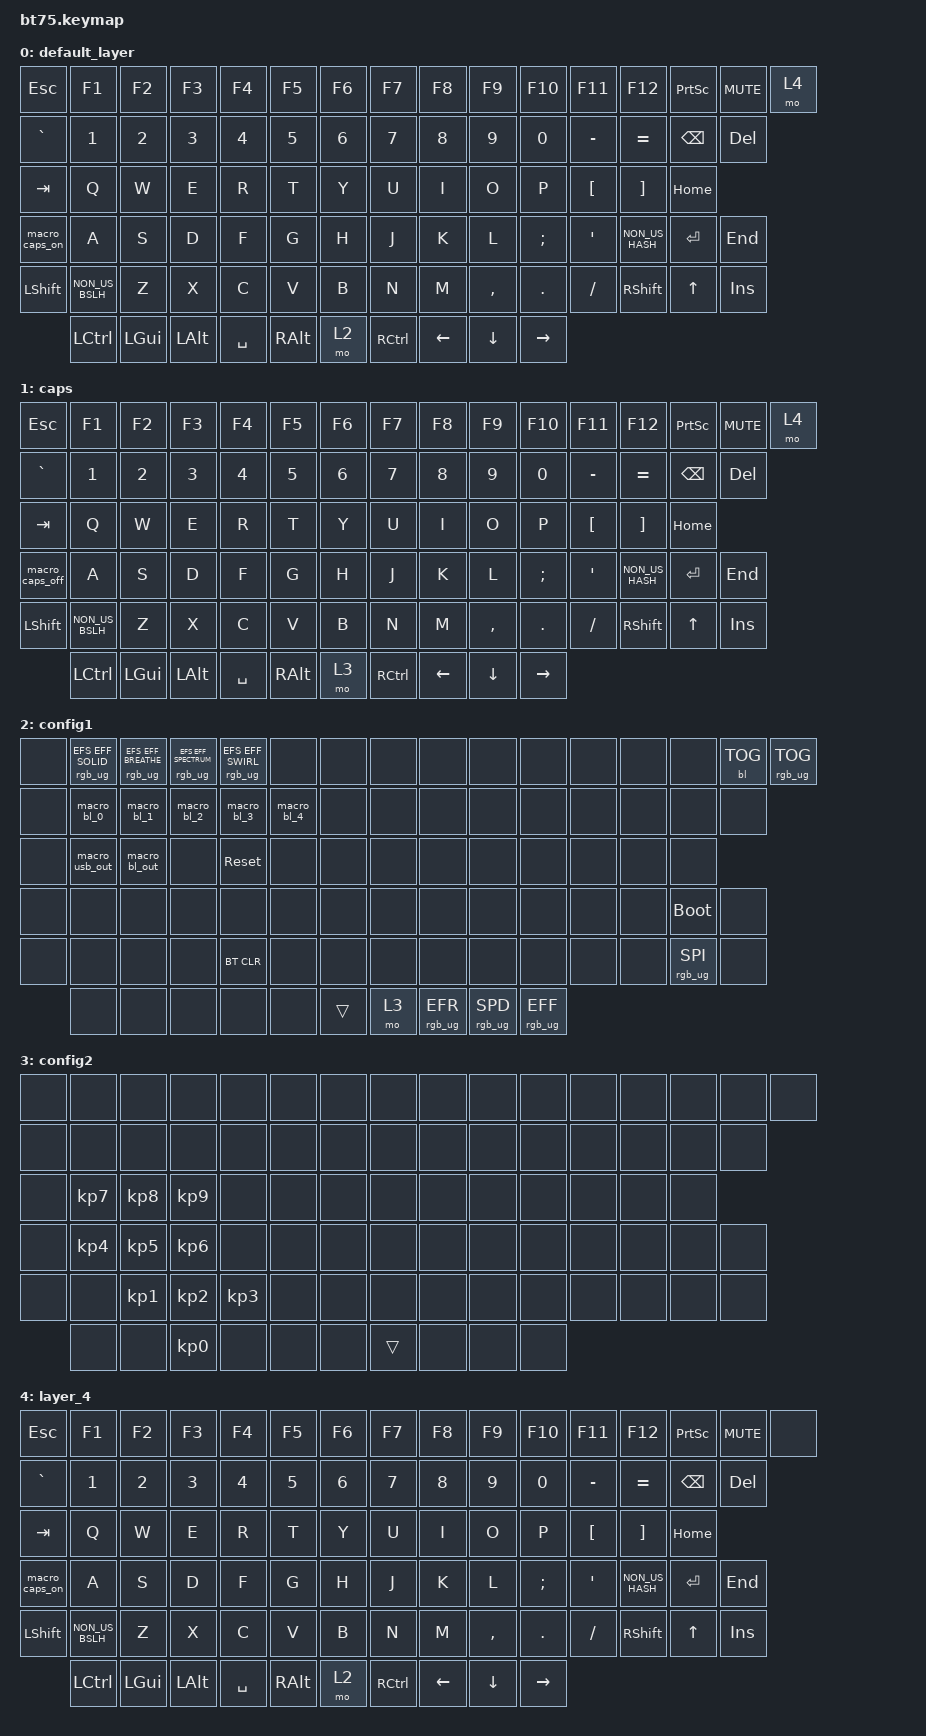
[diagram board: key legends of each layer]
#include <behaviors.dtsi>
#include <dt-bindings/zmk/backlight.h>
#include <dt-bindings/zmk/bt.h>
#include <dt-bindings/zmk/keys.h>
#include <dt-bindings/zmk/outputs.h>
#include <dt-bindings/zmk/rgb.h>

//&encoder_3 { resolution = <2>; };
//&encoder_2 { resolution = <2>; };

/ {
    behaviors {
        rgb_brightness: rgb_brightness {
            compatible = "zmk,behavior-sensor-rotate";
            label = "RGB_BRIGHTNESS";
            #sensor-binding-cells = <0>;
            bindings = <&rgb_ug RGB_BRD>, <&rgb_ug RGB_BRI>;
        };

        bl_brightness: bl_brightness {
            compatible = "zmk,behavior-sensor-rotate";
            label = "BL_BRIGHTNESS";
            #sensor-binding-cells = <0>;
            bindings = <&bl BL_DEC>, <&bl BL_INC>;
        };

        rgb_hue: rgb_hue {
            compatible = "zmk,behavior-sensor-rotate";
            label = "RGB_HUE";
            #sensor-binding-cells = <0>;
            bindings = <&rgb_ug RGB_HUD>, <&rgb_ug RGB_HUI>;
        };

        rgb_sat: rgb_sat {
            compatible = "zmk,behavior-sensor-rotate";
            label = "RGB_SAT";
            #sensor-binding-cells = <0>;
            bindings = <&rgb_ug RGB_SAD>, <&rgb_ug RGB_SAI>;
        };

        //rotary_toggle_press: behavior-toggle {
            //compatible = "zmk,behavior-toggle";
            //label = "ROTARY_TOGGLE_PRESS";
            //#sensor-binding-cells = <1>;
            //on-bindings = <&rotary_lr_mode>;
           // off-bindings = <&rotary_ud_mode>;
        //};

        //rotary_ud_mode: behavior-sensor-rotate-updown {
            //compatible = "zmk,behavior-sensor-rotate";
            //label = "ROTARY_UD_MODE";
            //#sensor-binding-cells = <1>;
           // bindings = <&kp UP>, <&kp DOWN>;
       // };

        //rotary_lr_mode: behavior-sensor-rotate-leftright {
           // compatible = "zmk,behavior-sensor-rotate";
            //label = "ROTARY_LR_MODE";
            //#sensor-binding-cells = <1>;
            //bindings = <&kp LEFT>, <&kp RIGHT>;
        //};

    };

    macros {
        macro_bl_0: macro_bl_0 {
            compatible = "zmk,behavior-macro";
            #binding-cells = <0>;
            bindings =
                <&macro_tap>,
                <&bt BT_SEL 0 &rgb_ug RGB_COLOR_HSB(190,100,100)>,
                <&macro_press>,
                <&rgb_ug RGB_MEFS RGB_EFF_SOLID>,
                <&macro_pause_for_release>,
                <&macro_release>,
                <&rgb_ug RGB_MEFS RGB_EFF_SOLID>;

            label = "macro_bl_0";
        };

        macro_bl_1: macro_bl_1 {
            compatible = "zmk,behavior-macro";
            #binding-cells = <0>;
            bindings =
                <&macro_tap>,
                <&bt BT_SEL 1 &rgb_ug RGB_COLOR_HSB(262,100,100)>,
                <&macro_press>,
                <&rgb_ug RGB_MEFS RGB_EFF_SOLID>,
                <&macro_pause_for_release>,
                <&macro_release>,
                <&rgb_ug RGB_MEFS RGB_EFF_SOLID>;

            label = "macro_bl_1";
        };

        macro_bl_2: macro_bl_2 {
            compatible = "zmk,behavior-macro";
            #binding-cells = <0>;
            bindings =
                <&macro_tap>,
                <&bt BT_SEL 2 &rgb_ug RGB_COLOR_HSB(334,100,100)>,
                <&macro_press>,
                <&rgb_ug RGB_MEFS RGB_EFF_SOLID>,
                <&macro_pause_for_release>,
                <&macro_release>,
                <&rgb_ug RGB_MEFS RGB_EFF_SOLID>;

            label = "macro_bl_2";
        };

        macro_bl_3: macro_bl_3 {
            compatible = "zmk,behavior-macro";
            #binding-cells = <0>;
            bindings =
                <&macro_tap>,
                <&bt BT_SEL 3 &rgb_ug RGB_COLOR_HSB(46,100,100)>,
                <&macro_press>,
                <&rgb_ug RGB_MEFS RGB_EFF_SOLID>,
                <&macro_pause_for_release>,
                <&macro_release>,
                <&rgb_ug RGB_MEFS RGB_EFF_SOLID>;

            label = "macro_bl_3";
        };

        macro_bl_4: macro_bl_4 {
            compatible = "zmk,behavior-macro";
            #binding-cells = <0>;
            bindings =
                <&macro_tap>,
                <&bt BT_SEL 4 &rgb_ug RGB_COLOR_HSB(118,100,100)>,
                <&macro_press>,
                <&rgb_ug RGB_MEFS RGB_EFF_SOLID>,
                <&macro_pause_for_release>,
                <&macro_release>,
                <&rgb_ug RGB_MEFS RGB_EFF_SOLID>;

            label = "macro_bl_4";
        };

        macro_bl_out: macro_bl_out {
            compatible = "zmk,behavior-macro";
            #binding-cells = <0>;
            bindings =
                <&macro_tap>,
                <&out OUT_BLE &rgb_ug RGB_COLOR_HSB(0,100,100)>,
                <&macro_press>,
                <&rgb_ug RGB_MEFS RGB_EFF_SOLID>,
                <&macro_pause_for_release>,
                <&macro_release>,
                <&rgb_ug RGB_MEFS RGB_EFF_SOLID>;

            label = "macro_bl_out";
        };

        macro_usb_out: macro_usb_out {
            compatible = "zmk,behavior-macro";
            #binding-cells = <0>;
            bindings =
                <&macro_tap>,
                <&out OUT_USB &rgb_ug RGB_COLOR_HSB(120,100,100)>,
                <&macro_press>,
                <&rgb_ug RGB_MEFS RGB_EFF_SOLID>,
                <&macro_pause_for_release>,
                <&macro_release>,
                <&rgb_ug RGB_MEFS RGB_EFF_SOLID>;

            label = "macro_usb_out";
        };

        macro_caps_on: macro_caps_on {
            compatible = "zmk,behavior-macro";
            #binding-cells = <0>;
            bindings =
                <&macro_tap>,
                <&to 1 &rgb_ug RGB_COLOR_HSB(0,100,100) &kp CAPSLOCK>,
                <&macro_press>,
                <&rgb_ug RGB_MEFS RGB_EFF_SOLID>;

            label = "macro_caps_on";
        };

        macro_caps_off: macro_caps_off {
            compatible = "zmk,behavior-macro";
            #binding-cells = <0>;
            bindings =
                <&macro_tap>,
                <&to 0 &kp CAPSLOCK>,
                <&macro_release>,
                <&rgb_ug RGB_MEFS RGB_EFF_SOLID>;

            label = "macro_caps_off";
        };
    };

    keymap {
        compatible = "zmk,keymap";

        default_layer {
            // ------------------------------------------------------------------------------------------------------------
            // | ESC | F1  | F2  | F3  | F4  | F5  | F6  | F7  | F9  | F9  | F10 | F11 | F12 | PSCRN | INS | DEL	|
            // |  `  |  1  |  2  |  3  |  4  |  5  |  6  |  7  |  8  |  9  |  0  |  -  |  =  |   BKSP   | HOME	|
            // | TAB  |  Q  |  W  |  E  |  R  |  T  |  Y  |  U  |  I  |  O  |  P  |  [  |  ]  |        | PG UP |
            // | CAPS  |  A  |  S  |  D  |  F  |  G  |  H  |  J  |  K  |  L  |  ;  |  '  |   # | ENTER     | PG DN |
            // |  SHIFT | \   |  Z  |  X  |  C  |  V  |  B  |  N  |  M  |  ,  |  .  | /   |    SHIFT |  UP  |  END  |
            // |  CTL  |  WIN  |  ALT  |            SPACE               | ALT | 1  | CTRL |  LEFT | DOWN | RIGHT |
            // ------------------------------------------------------------------------------------------------------------

            bindings = <
&kp ESC         &kp F1           &kp F2    &kp F3    &kp F4     &kp F5    &kp F6  &kp F7     &kp F8    &kp F9     &kp F10    &kp F11    &kp F12          &kp PSCRN      &kp C_MUTE  &mo 4
&kp GRAVE       &kp N1           &kp N2    &kp N3    &kp N4     &kp N5    &kp N6  &kp N7     &kp N8    &kp N9     &kp N0     &kp MINUS  &kp EQUAL        &kp BACKSPACE  &kp DELETE
&kp TAB         &kp Q            &kp W     &kp E     &kp R      &kp T     &kp Y   &kp U      &kp I     &kp O      &kp P      &kp LBKT   &kp RBKT         &kp HOME
&macro_caps_on  &kp A            &kp S     &kp D     &kp F      &kp G     &kp H   &kp J      &kp K     &kp L      &kp SEMI   &kp SQT    &kp NON_US_HASH  &kp RET        &kp END
&kp LSHFT       &kp NON_US_BSLH  &kp Z     &kp X     &kp C      &kp V     &kp B   &kp N      &kp M     &kp COMMA  &kp DOT    &kp FSLH   &kp RSHFT        &kp UP         &kp INS
                &kp LCTRL        &kp LGUI  &kp LALT  &kp SPACE  &kp RALT  &mo 2   &kp RCTRL  &kp LEFT  &kp DOWN   &kp RIGHT
            >;

            sensor-bindings =
                <&inc_dec_kp C_VOL_DN C_VOL_UP>,
                <&inc_dec_kp UP DOWN>;
        };

        caps {
            bindings = <
&kp ESC          &kp F1           &kp F2    &kp F3    &kp F4     &kp F5    &kp F6  &kp F7     &kp F8    &kp F9     &kp F10    &kp F11    &kp F12          &kp PSCRN      &kp C_MUTE  &mo 4
&kp GRAVE        &kp N1           &kp N2    &kp N3    &kp N4     &kp N5    &kp N6  &kp N7     &kp N8    &kp N9     &kp N0     &kp MINUS  &kp EQUAL        &kp BACKSPACE  &kp DELETE
&kp TAB          &kp Q            &kp W     &kp E     &kp R      &kp T     &kp Y   &kp U      &kp I     &kp O      &kp P      &kp LBKT   &kp RBKT         &kp HOME
&macro_caps_off  &kp A            &kp S     &kp D     &kp F      &kp G     &kp H   &kp J      &kp K     &kp L      &kp SEMI   &kp SQT    &kp NON_US_HASH  &kp RET        &kp END
&kp LSHFT        &kp NON_US_BSLH  &kp Z     &kp X     &kp C      &kp V     &kp B   &kp N      &kp M     &kp COMMA  &kp DOT    &kp FSLH   &kp RSHFT        &kp UP         &kp INS
                 &kp LCTRL        &kp LGUI  &kp LALT  &kp SPACE  &kp RALT  &mo 3   &kp RCTRL  &kp LEFT  &kp DOWN   &kp RIGHT
            >;

            sensor-bindings =
                <&inc_dec_kp C_VOL_DN C_VOL_UP>,
                <&inc_dec_kp UP DOWN>;
        };

        config1 {
            bindings = <
&none  &rgb_ug RGB_EFS RGB_EFF_SOLID  &rgb_ug RGB_EFS RGB_EFF_BREATHE  &rgb_ug RGB_EFS RGB_EFF_SPECTRUM  &rgb_ug RGB_EFS RGB_EFF_SWIRL  &none        &none   &none  &none            &none            &none            &none  &none  &none            &bl BL_TOG  &rgb_ug RGB_TOG
&none  &macro_bl_0                    &macro_bl_1                      &macro_bl_2                       &macro_bl_3                    &macro_bl_4  &none   &none  &none            &none            &none            &none  &none  &none            &none
&none  &macro_usb_out                 &macro_bl_out                    &none                             &sys_reset                     &none        &none   &none  &none            &none            &none            &none  &none  &none
&none  &none                          &none                            &none                             &none                          &none        &none   &none  &none            &none            &none            &none  &none  &bootloader      &none
&none  &none                          &none                            &none                             &bt BT_CLR                     &none        &none   &none  &none            &none            &none            &none  &none  &rgb_ug RGB_SPI  &none
       &none                          &none                            &none                             &none                          &none        &trans  &mo 3  &rgb_ug RGB_EFR  &rgb_ug RGB_SPD  &rgb_ug RGB_EFF
            >;

            sensor-bindings = <&bl_brightness &rgb_brightness>;
        };

        config2 {
            bindings = <
&none  &none      &none      &none            &none      &none  &none  &none   &none  &none  &none  &none  &none  &none  &none  &none
&none  &none      &none      &none            &none      &none  &none  &none   &none  &none  &none  &none  &none  &none  &none
&none  &kp KP_N7  &kp KP_N8  &kp KP_N9        &none      &none  &none  &none   &none  &none  &none  &none  &none  &none
&none  &kp KP_N4  &kp KP_N5  &kp KP_N6        &none      &none  &none  &none   &none  &none  &none  &none  &none  &none  &none
&none  &none      &kp KP_N1  &kp KP_NUMBER_2  &kp KP_N3  &none  &none  &none   &none  &none  &none  &none  &none  &none  &none
       &none      &none      &kp KP_N0        &none      &none  &none  &trans  &none  &none  &none
            >;

            sensor-bindings = <&rgb_sat &rgb_hue>;
        };

        layer_4 {
            bindings = <
&kp ESC         &kp F1           &kp F2    &kp F3    &kp F4     &kp F5    &kp F6  &kp F7     &kp F8    &kp F9     &kp F10    &kp F11    &kp F12          &kp PSCRN      &kp C_MUTE  &none
&kp GRAVE       &kp N1           &kp N2    &kp N3    &kp N4     &kp N5    &kp N6  &kp N7     &kp N8    &kp N9     &kp N0     &kp MINUS  &kp EQUAL        &kp BACKSPACE  &kp DELETE
&kp TAB         &kp Q            &kp W     &kp E     &kp R      &kp T     &kp Y   &kp U      &kp I     &kp O      &kp P      &kp LBKT   &kp RBKT         &kp HOME
&macro_caps_on  &kp A            &kp S     &kp D     &kp F      &kp G     &kp H   &kp J      &kp K     &kp L      &kp SEMI   &kp SQT    &kp NON_US_HASH  &kp RET        &kp END
&kp LSHFT       &kp NON_US_BSLH  &kp Z     &kp X     &kp C      &kp V     &kp B   &kp N      &kp M     &kp COMMA  &kp DOT    &kp FSLH   &kp RSHFT        &kp UP         &kp INS
                &kp LCTRL        &kp LGUI  &kp LALT  &kp SPACE  &kp RALT  &mo 2   &kp RCTRL  &kp LEFT  &kp DOWN   &kp RIGHT
            >;

            sensor-bindings =
                <&inc_dec_kp C_VOL_DN C_VOL_UP>,
                <&inc_dec_kp LEFT_ARROW RIGHT>;
        };
    };
};
